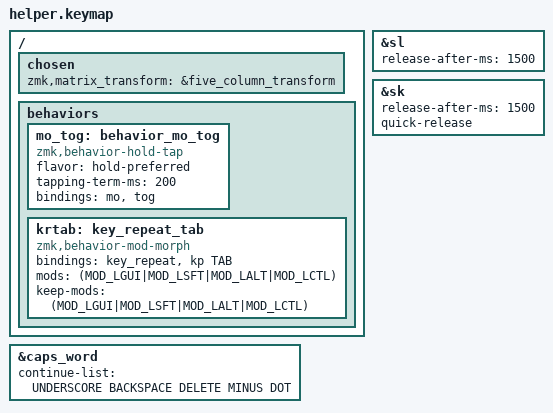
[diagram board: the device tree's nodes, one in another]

// layers
#define QWERTY   0
#define NUMBERS  1
#define CODING   2
#define CONTROLS 3
#define AFK      4

#define CUSTOM_HELPER_STRINGIFY(x) #x

#define CUSTOM_LAYER(layer, display_name, layer_bindings) \
/ { \
  keymap { \
    compatible = "zmk,keymap"; \
    layer { \
      label = display_name; \
      bindings = <layer_bindings>; \
    }; \
  }; \
};

#define CUSTOM_COMBO(name, keypos, combo_bindings) \
/ { \
  combos { \
    compatible = "zmk,combos"; \
      combo_##name { \
        timeout-ms = <30>; \
        slow-release; \
        key-positions = <keypos>; \
        bindings = <combo_bindings>; \
        layers = <0 1 2 3>; \
      }; \
  }; \
};

#define CUSTOM_COMBO_PANIC(name, keypos, combo_bindings) \
/ { \
  combos { \
    compatible = "zmk,combos"; \
      combo_##name { \
        timeout-ms = <30>; \
        slow-release; \
        key-positions = <keypos>; \
        bindings = <combo_bindings>; \
      }; \
  }; \
};

#define CUSTOM_MACRO(name, macro_bindings) \
/ { \
  macros { \
    name: name { \
      compatible = "zmk,behavior-macro"; \
      #binding-cells = <0>; \
      wait-ms = <40>; \
      tap-ms = <40>; \
      bindings = <macro_bindings>; \
    }; \
  }; \
};

/ {
  chosen {
    zmk,matrix_transform = &five_column_transform;
  };
};

// sticky keys behaviors
&sl {
  release-after-ms = <1500>;
};

&sk {
  release-after-ms = <1500>;
  quick-release;
};

// caps
&caps_word {
  continue-list = <UNDERSCORE BACKSPACE DELETE MINUS DOT>;
};

/ {
  behaviors {
    mo_tog: behavior_mo_tog {
      compatible = "zmk,behavior-hold-tap";
      #binding-cells = <2>;
      flavor = "hold-preferred";
      tapping-term-ms = <200>;
      bindings = <&mo>, <&tog>;
    };
  };
};

/ {
  behaviors {
    // mod-morphs
    krtab: key_repeat_tab {
      compatible = "zmk,behavior-mod-morph";
      #binding-cells = <0>;
      bindings = <&key_repeat>, <&kp TAB>;
      mods = <(MOD_LGUI|MOD_LSFT|MOD_LALT|MOD_LCTL)>;
      keep-mods = <(MOD_LGUI|MOD_LSFT|MOD_LALT|MOD_LCTL)>;
    };
  };
};
